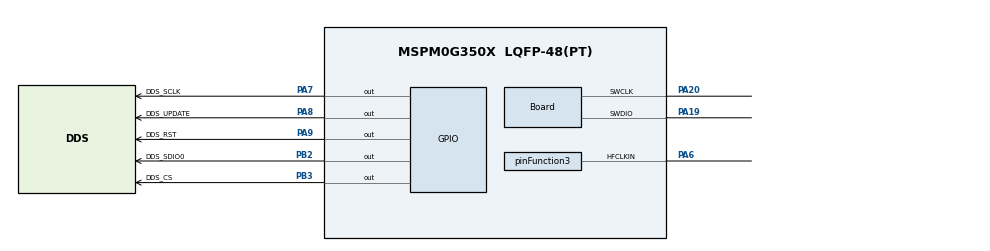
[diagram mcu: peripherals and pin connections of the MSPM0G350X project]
/**
 * @cliArgs --device "MSPM0G350X" --package "LQFP-48(PT)" --part "Default" --product "mspm0_sdk@2.00.01.01"
 * @versions {"tool":"1.19.0+3426"}
 */

/**
 * Import the modules used in this configuration.
 */
const GPIO          = scripting.addModule("/ti/driverlib/GPIO", {}, false);
const GPIO1         = GPIO.addInstance();
const SYSCTL        = scripting.addModule("/ti/driverlib/SYSCTL");
const SYSTICK       = scripting.addModule("/ti/driverlib/SYSTICK");
const ProjectConfig = scripting.addModule("/ti/project_config/ProjectConfig");

/**
 * Write custom configuration values to the imported modules.
 */
const divider9       = system.clockTree["UDIV"];
divider9.divideValue = 2;

const multiplier2         = system.clockTree["PLL_QDIV"];
multiplier2.multiplyValue = 4;

const mux2       = system.clockTree["CANCLKMUX"];
mux2.inputSelect = "CANCLKMUX_PLLCLK1_OUT";

const mux8       = system.clockTree["HSCLKMUX"];
mux8.inputSelect = "HSCLKMUX_SYSPLL0";

const mux12       = system.clockTree["SYSPLLMUX"];
mux12.inputSelect = "zSYSPLLMUX_HFCLK";

const pinFunction3                         = system.clockTree["HFCLKEXT"];
pinFunction3.enable                        = true;
pinFunction3.inputFreq                     = 40;
pinFunction3.peripheral.$assign            = "SYSCTL";
pinFunction3.peripheral.hfclkInPin.$assign = "PA6";

GPIO1.$name                          = "GPIO_DDS";
GPIO1.associatedPins.create(5);
GPIO1.associatedPins[0].$name        = "DDS_SCLK";
GPIO1.associatedPins[0].assignedPort = "PORTA";
GPIO1.associatedPins[0].assignedPin  = "7";
GPIO1.associatedPins[0].pin.$assign  = "PA7";
GPIO1.associatedPins[1].$name        = "DDS_SDIO0";
GPIO1.associatedPins[1].assignedPort = "PORTB";
GPIO1.associatedPins[1].assignedPin  = "2";
GPIO1.associatedPins[1].pin.$assign  = "PB2";
GPIO1.associatedPins[2].$name        = "DDS_CS";
GPIO1.associatedPins[2].assignedPort = "PORTB";
GPIO1.associatedPins[2].assignedPin  = "3";
GPIO1.associatedPins[2].pin.$assign  = "PB3";
GPIO1.associatedPins[3].$name        = "DDS_UPDATE";
GPIO1.associatedPins[3].assignedPort = "PORTA";
GPIO1.associatedPins[3].assignedPin  = "8";
GPIO1.associatedPins[3].pin.$assign  = "PA8";
GPIO1.associatedPins[4].$name        = "DDS_RST";
GPIO1.associatedPins[4].assignedPort = "PORTA";
GPIO1.associatedPins[4].assignedPin  = "9";
GPIO1.associatedPins[4].pin.$assign  = "PA9";

const Board                       = scripting.addModule("/ti/driverlib/Board", {}, false);
Board.peripheral.$assign          = "DEBUGSS";
Board.peripheral.swclkPin.$assign = "PA20";
Board.peripheral.swdioPin.$assign = "PA19";

SYSCTL.clockTreeEn = true;

SYSTICK.periodEnable    = true;
SYSTICK.period          = 80000;
SYSTICK.interruptEnable = true;
SYSTICK.systickEnable   = true;

ProjectConfig.deviceSpin = "MSPM0G3507";
scripting.suppress("Migrating requires going through the Switch Board or Device menu in the Device View section\\.", ProjectConfig, "deviceSpin");
